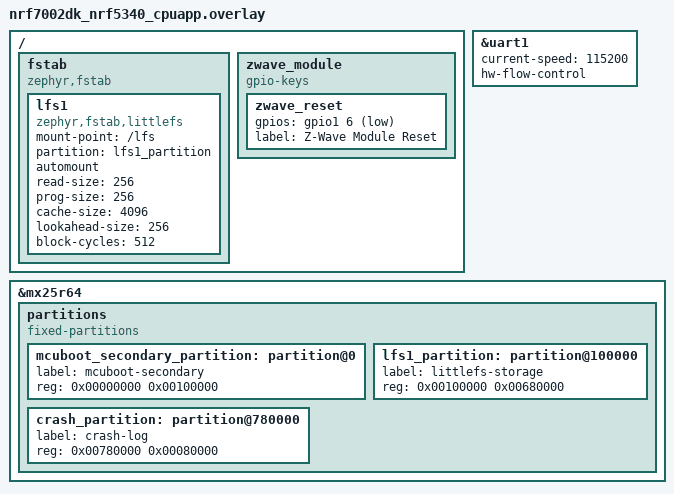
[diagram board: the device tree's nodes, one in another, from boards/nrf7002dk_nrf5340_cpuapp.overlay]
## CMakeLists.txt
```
cmake_minimum_required(VERSION 3.20.0)
find_package(Zephyr REQUIRED HINTS $ENV{ZEPHYR_BASE})
project(shgw)

target_sources(app PRIVATE
    src/main.c
    src/storage_mgr/storage_mgr.c
    src/system_mgr/system_mgr.c
    src/shell/shell_shg.c
    src/shell/shell_fs.c
)

target_include_directories(app PRIVATE
    src/
)
```

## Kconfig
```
mainmenu "Smart Home Gateway Configuration"

source "Kconfig.zephyr"

config SHG_SHELL_PRODUCTION
	bool "Enable production shell commands"
	default y
	help
	  Enables the production shell command set (shg info, fs ls, fs cat).

config SHG_SHELL_DEBUG
	bool "Enable debug shell commands"
	default n
	help
	  Enables additional debug shell commands (thread info, memory dump).

config SYSTEM_MGR_LOG_LEVEL
	int "System Manager log level"
	default 3
	help
	  Log level for the system_mgr module (0=OFF, 1=ERR, 2=WRN, 3=INF, 4=DBG).

config STORAGE_MGR_LOG_LEVEL
	int "Storage Manager log level"
	default 3
	help
	  Log level for the storage_mgr module (0=OFF, 1=ERR, 2=WRN, 3=INF, 4=DBG).
```

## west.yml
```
manifest:
  remotes:
    - name: nrfconnect
      url-base: https://github.com/nrfconnect
  projects:
    - name: sdk-nrf
      remote: nrfconnect
      revision: v2.9.0
      import: true
  self:
    path: shgw
```

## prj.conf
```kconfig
# ============================================================================
# Phase 1: Bare OS + Emulation Foundation
# ============================================================================

# --- Kernel ---
CONFIG_MAIN_STACK_SIZE=4096
CONFIG_SYSTEM_WORKQUEUE_STACK_SIZE=2048
CONFIG_HEAP_MEM_POOL_SIZE=16384

# --- Flash ---
CONFIG_FLASH=y
CONFIG_FLASH_MAP=y
CONFIG_FLASH_PAGE_LAYOUT=y

# --- File System (LittleFS) ---
CONFIG_FILE_SYSTEM=y
CONFIG_FILE_SYSTEM_LITTLEFS=y

# --- Non-Volatile Storage ---
CONFIG_NVS=y
CONFIG_NVS_LOG_LEVEL_WRN=y

# --- Shell ---
CONFIG_SHELL=y
CONFIG_SHELL_BACKEND_SERIAL=y
CONFIG_SHELL_LOG_BACKEND=y

# --- Logging ---
CONFIG_LOG=y
CONFIG_LOG_MODE_DEFERRED=y
CONFIG_LOG_BACKEND_UART=y

# --- Thread naming ---
CONFIG_THREAD_NAME=y
```

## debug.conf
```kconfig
# ============================================================================
# Debug overlay — additive to prj.conf
# ============================================================================

CONFIG_THREAD_ANALYZER=y
CONFIG_THREAD_ANALYZER_USE_PRINTK=y
CONFIG_THREAD_ANALYZER_AUTO=y
CONFIG_THREAD_ANALYZER_AUTO_INTERVAL=60
```

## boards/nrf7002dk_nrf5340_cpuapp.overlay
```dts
/ {
	fstab {
		compatible = "zephyr,fstab";
		lfs1: lfs1 {
			compatible = "zephyr,fstab,littlefs";
			mount-point = "/lfs";
			partition = <&lfs1_partition>;
			automount;
			read-size = <256>;
			prog-size = <256>;
			cache-size = <4096>;
			lookahead-size = <256>;
			block-cycles = <512>;
		};
	};

	zwave_module {
		compatible = "gpio-keys";
		zwave_reset: zwave_reset {
			gpios = <&gpio1 6 GPIO_ACTIVE_LOW>;
			label = "Z-Wave Module Reset";
		};
	};
};

&uart1 {
	status = "okay";
	current-speed = <115200>;
	hw-flow-control;
};

&mx25r64 {
	partitions {
		compatible = "fixed-partitions";
		#address-cells = <1>;
		#size-cells = <1>;

		mcuboot_secondary_partition: partition@0 {
			label = "mcuboot-secondary";
			reg = <0x00000000 0x00100000>;
		};
		lfs1_partition: partition@100000 {
			label = "littlefs-storage";
			reg = <0x00100000 0x00680000>;
		};
		crash_partition: partition@780000 {
			label = "crash-log";
			reg = <0x00780000 0x00080000>;
		};
	};
};
```

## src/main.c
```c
/* =========================================================================
 * src/main.c — Application entry point (Phase 1)
 * ========================================================================= */
#include <zephyr/kernel.h>
#include <zephyr/logging/log.h>
#include <app_version.h>

#include "storage_mgr/storage_mgr.h"
#include "system_mgr/system_mgr.h"

LOG_MODULE_REGISTER(main, LOG_LEVEL_INF);

int main(void)
{
	int ret;

	/* 1. Initialize storage (LittleFS + NVS) — must be first */
	ret = storage_mgr_init();
	if (ret != 0) {
		LOG_ERR("Storage init failed: %d", ret);
		return ret;
	}

	/* 2. Initialize System Manager (reads NVS, transitions state) */
	ret = system_mgr_init();
	if (ret != 0) {
		LOG_ERR("System Manager init failed: %d", ret);
	}

	/* 3. Increment and persist boot count */
	uint32_t boot_count = 0;

	ret = storage_mgr_nvs_read(NVS_ID_BOOT_COUNT, &boot_count,
				   sizeof(boot_count));
	if (ret < 0) {
		boot_count = 0; /* First boot — key not found */
	}
	boot_count++;

	ret = storage_mgr_nvs_write(NVS_ID_BOOT_COUNT, &boot_count,
				    sizeof(boot_count));
	if (ret != 0) {
		LOG_ERR("Failed to write boot count: %d", ret);
	}

	/* 4. Log boot info */
	LOG_INF("=== Smart Home Gateway ===");
	LOG_INF("Firmware : v%s", APP_VERSION_STRING);
	LOG_INF("Boot count: %u", boot_count);
	LOG_INF("State    : %s",
		system_mgr_state_name(system_mgr_get_state()));

	/* Shell is auto-started by Zephyr shell subsystem.
	 * main() returns and scheduler takes over. */
	return 0;
}
```
